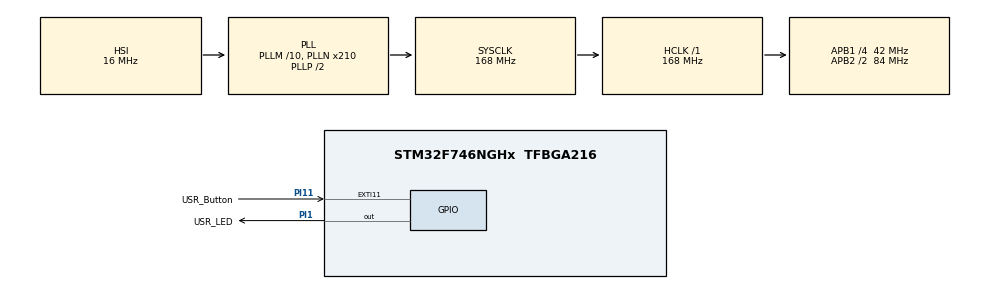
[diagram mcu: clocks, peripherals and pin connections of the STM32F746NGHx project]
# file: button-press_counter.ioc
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Mcu.Family=STM32F7
Mcu.Name=STM32F746NGHx
Mcu.Package=TFBGA216
NVIC.EXTI15_10_IRQn=true\:0\:0\:false\:false\:true\:true\:true
NVIC.PriorityGroup=NVIC_PRIORITYGROUP_4
NVIC.TIM8_TRG_COM_TIM14_IRQn=true\:0\:0\:false\:false\:true\:false\:true
NVIC.TimeBase=TIM8_TRG_COM_TIM14_IRQn
NVIC.TimeBaseIP=TIM14
PA13.Mode=Serial_Wire
PA13.Signal=SYS_JTMS-SWDIO
PA14.Mode=Serial_Wire
PA14.Signal=SYS_JTCK-SWCLK
PC14/OSC32_IN.Mode=LSE-External-Clock-Source
PC14/OSC32_IN.Signal=RCC_OSC32_IN
PC15/OSC32_OUT.Mode=LSE-External-Clock-Source
PC15/OSC32_OUT.Signal=RCC_OSC32_OUT
PH0/OSC_IN.Mode=HSE-External-Oscillator
PH0/OSC_IN.Signal=RCC_OSC_IN
PH1/OSC_OUT.Mode=HSE-External-Oscillator
PH1/OSC_OUT.Signal=RCC_OSC_OUT
PI1.GPIO_Label=USR_LED
PI1.GPIO_PuPd=GPIO_NOPULL
PI1.Signal=GPIO_Output
PI11.GPIO_Label=USR_Button
PI11.GPIO_PuPd=GPIO_PULLDOWN
PI11.Signal=GPXTI11
ProjectManager.HeapSize=0x200
ProjectManager.StackSize=0x400
ProjectManager.TargetToolchain=STM32CubeIDE
RCC.AHBFreq_Value=168000000
RCC.APB1CLKDivider=RCC_HCLK_DIV4
RCC.APB1Freq_Value=42000000
RCC.APB1TimFreq_Value=84000000
RCC.APB2CLKDivider=RCC_HCLK_DIV2
RCC.APB2Freq_Value=84000000
RCC.APB2TimFreq_Value=168000000
RCC.CortexFreq_Value=168000000
RCC.HCLKFreq_Value=168000000
RCC.HSE_VALUE=25000000
RCC.HSI_VALUE=16000000
RCC.LSE_VALUE=32768
RCC.PLLM=10
RCC.PLLN=210
RCC.PLLSourceVirtual=RCC_PLLSOURCE_HSI
RCC.SYSCLKFreq_VALUE=168000000
RCC.SYSCLKSource=RCC_SYSCLKSOURCE_PLLCLK
RCC.USBFreq_Value=168000000
RCC.VCOOutputFreq_Value=336000000
VP_SYS_VS_tim14.Mode=TIM14
board=STM32F746G-DISCO

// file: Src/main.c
/* USER CODE BEGIN Header */
/**
  ******************************************************************************
  * @file           : main.c
  * @brief          : Main program body
  ******************************************************************************
  * @attention
  *
  * <h2><center>&copy; Copyright (c) 2019 STMicroelectronics.
  * All rights reserved.</center></h2>
  *
  * This software component is licensed by ST under BSD 3-Clause license,
  * the "License"; You may not use this file except in compliance with the
  * License. You may obtain a copy of the License at:
  *                        opensource.org/licenses/BSD-3-Clause
  *
  ******************************************************************************
  */
/* USER CODE END Header */

#include "main.h"

/* USER CODE BEGIN PTD */

typedef enum led_state{
	OFF,
	ON
} led_state_t;

/* USER CODE END PTD */

/* USER CODE BEGIN PV */

led_state_t led_state = OFF;

volatile unsigned int button_presses = 0;

/* USER CODE END PV */

void SystemClock_Config(void);
static void MX_GPIO_Init(void);

int main(void)
{

  /* MCU Configuration--------------------------------------------------------*/

  /* Reset of all peripherals, Initializes the Flash interface and the Systick. */
  HAL_Init();

  /* Configure the system clock */
  SystemClock_Config();

  /* Initialize all configured peripherals */
  MX_GPIO_Init();

  /* Infinite loop */
  while (1)
  {

    /* USER CODE BEGIN 3 */

		if (button_presses == 5){
			HAL_GPIO_TogglePin(USR_LED_GPIO_Port, USR_LED_Pin);
			led_state = ON;
			}

  }
  /* USER CODE END 3 */
}

void SystemClock_Config(void)
{
  RCC_OscInitTypeDef RCC_OscInitStruct = {0};
  RCC_ClkInitTypeDef RCC_ClkInitStruct = {0};

  /** Configure the main internal regulator output voltage
  */
  __HAL_RCC_PWR_CLK_ENABLE();
  __HAL_PWR_VOLTAGESCALING_CONFIG(PWR_REGULATOR_VOLTAGE_SCALE2);
  /** Initializes the CPU, AHB and APB busses clocks
  */
  RCC_OscInitStruct.OscillatorType = RCC_OSCILLATORTYPE_HSI;
  RCC_OscInitStruct.HSIState = RCC_HSI_ON;
  RCC_OscInitStruct.HSICalibrationValue = RCC_HSICALIBRATION_DEFAULT;
  RCC_OscInitStruct.PLL.PLLState = RCC_PLL_ON;
  RCC_OscInitStruct.PLL.PLLSource = RCC_PLLSOURCE_HSI;
  RCC_OscInitStruct.PLL.PLLM = 10;
  RCC_OscInitStruct.PLL.PLLN = 210;
  RCC_OscInitStruct.PLL.PLLP = RCC_PLLP_DIV2;
  RCC_OscInitStruct.PLL.PLLQ = 2;
  if (HAL_RCC_OscConfig(&RCC_OscInitStruct) != HAL_OK)
  {
    Error_Handler();
  }
  /** Initializes the CPU, AHB and APB busses clocks
  */
  RCC_ClkInitStruct.ClockType = RCC_CLOCKTYPE_HCLK|RCC_CLOCKTYPE_SYSCLK
                              |RCC_CLOCKTYPE_PCLK1|RCC_CLOCKTYPE_PCLK2;
  RCC_ClkInitStruct.SYSCLKSource = RCC_SYSCLKSOURCE_PLLCLK;
  RCC_ClkInitStruct.AHBCLKDivider = RCC_SYSCLK_DIV1;
  RCC_ClkInitStruct.APB1CLKDivider = RCC_HCLK_DIV4;
  RCC_ClkInitStruct.APB2CLKDivider = RCC_HCLK_DIV2;

  if (HAL_RCC_ClockConfig(&RCC_ClkInitStruct, FLASH_LATENCY_5) != HAL_OK)
  {
    Error_Handler();
  }
}

static void MX_GPIO_Init(void)
{
  GPIO_InitTypeDef GPIO_InitStruct = {0};

  /* GPIO Ports Clock Enable */
  __HAL_RCC_GPIOA_CLK_ENABLE();
  __HAL_RCC_GPIOI_CLK_ENABLE();
  __HAL_RCC_GPIOC_CLK_ENABLE();
  __HAL_RCC_GPIOH_CLK_ENABLE();

  /*Configure GPIO pin Output Level */
  HAL_GPIO_WritePin(USR_LED_GPIO_Port, USR_LED_Pin, GPIO_PIN_RESET);

  /*Configure GPIO pin : USR_LED_Pin */
  GPIO_InitStruct.Pin = USR_LED_Pin;
  GPIO_InitStruct.Mode = GPIO_MODE_OUTPUT_PP;
  GPIO_InitStruct.Pull = GPIO_NOPULL;
  GPIO_InitStruct.Speed = GPIO_SPEED_FREQ_LOW;
  HAL_GPIO_Init(USR_LED_GPIO_Port, &GPIO_InitStruct);

  /*Configure GPIO pin : USR_Button_Pin */
  GPIO_InitStruct.Pin = USR_Button_Pin;
  GPIO_InitStruct.Mode = GPIO_MODE_IT_RISING;
  GPIO_InitStruct.Pull = GPIO_PULLDOWN;
  HAL_GPIO_Init(USR_Button_GPIO_Port, &GPIO_InitStruct);

  /* EXTI interrupt init*/
  HAL_NVIC_SetPriority(EXTI15_10_IRQn, 0, 0);
  HAL_NVIC_EnableIRQ(EXTI15_10_IRQn);

}

/* USER CODE BEGIN 4 */

void HAL_GPIO_EXTI_Callback(uint16_t GPIO_Pin)
{
	if(led_state == OFF){

		button_presses++;

	}
}

/* USER CODE END 4 */

void HAL_TIM_PeriodElapsedCallback(TIM_HandleTypeDef *htim)
{
  if (htim->Instance == TIM14) {
    HAL_IncTick();
  }
}

void Error_Handler(void)
{
}

/************************ (C) COPYRIGHT STMicroelectronics *****END OF FILE****/
